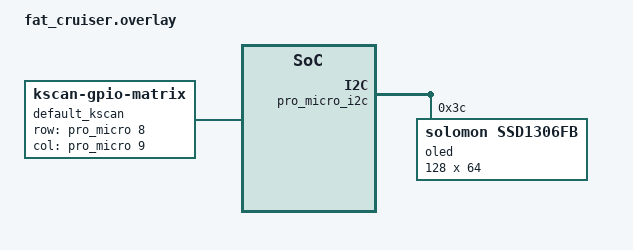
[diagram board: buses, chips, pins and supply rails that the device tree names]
#include <dt-bindings/zmk/matrix_transform.h>

/ {
    chosen {
        zmk,kscan = &default_kscan;
        zmk,matrix-transform = &default_transform;
        zephyr,display = &oled;
    };

    default_kscan: kscan {
        compatible = "zmk,kscan-gpio-matrix";
        diode-direction = "col2row";

        row-gpios = <&pro_micro 8 (GPIO_ACTIVE_HIGH | GPIO_PULL_DOWN)>;
        col-gpios = <&pro_micro 9 GPIO_ACTIVE_HIGH>;
    };

    default_transform: matrix_transform {
        compatible = "zmk,matrix-transform";

        rows = <1>;
        columns = <1>;

        map = <
            RC(0,0)
        >;
    };
};

/* OLED display */
&pro_micro_i2c {
    status = "okay";

    oled: ssd1306@3c {
        compatible = "solomon,ssd1306fb";
        reg = <0x3c>;
        width = <128>;
        height = <64>;
        segment-offset = <0>;
        page-offset = <0>;
        display-offset = <0>;
        multiplex-ratio = <63>;
        segment-remap;
        com-invdir;
        inversion-on;
        prechargep = <0x22>;
        ready-time-ms = <100>;
    };
};
